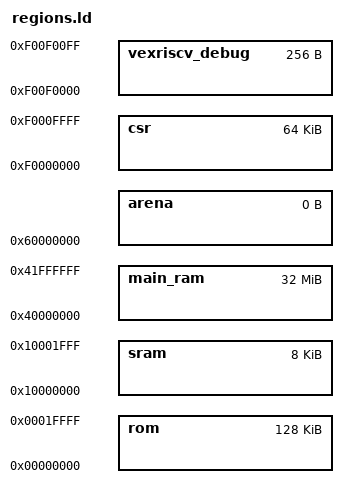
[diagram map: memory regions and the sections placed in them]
MEMORY {
	vexriscv_debug : ORIGIN = 0xf00f0000, LENGTH = 0x00000100
	rom : ORIGIN = 0x00000000, LENGTH = 0x00020000
	sram : ORIGIN = 0x10000000, LENGTH = 0x00002000
	main_ram : ORIGIN = 0x40000000, LENGTH = 0x02000000
	arena : ORIGIN = 0x60000000, LENGTH = 0x00000000
	csr : ORIGIN = 0xf0000000, LENGTH = 0x00010000
}
